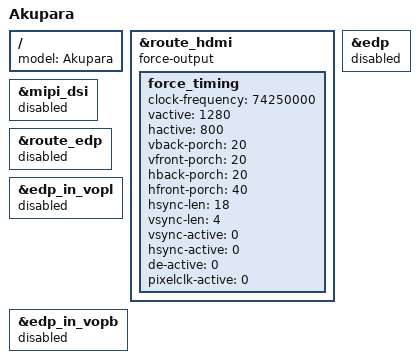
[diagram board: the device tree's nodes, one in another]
/*
 * (C) Copyright 2016 Rockchip Electronics Co., Ltd
 *
 * SPDX-License-Identifier:     GPL-2.0+
 */

/dts-v1/;
#include "rockpi-4b.dts"

/ {
	model = "Akupara";
};

&route_hdmi {
	status = "okay";
	force-output;

	force_timing {
		status = "okay";
		clock-frequency = <74250000>;
		vactive = <1280>;
		hactive = <800>;
		vback-porch = <20>;
		vfront-porch = <20>;
		hback-porch = <20>;
		hfront-porch = <40>;
		hsync-len = <18>;
		vsync-len = <4>;
		vsync-active = <0>;
		hsync-active = <0>;
		de-active = <0>;
		pixelclk-active = <0>;
	};
};

&mipi_dsi {
	status = "disabled";
};

&route_edp {
	status = "disabled";
};

&edp_in_vopl {
	status = "disabled";
};

&edp_in_vopb {
	status = "disabled";
};

&edp {
	status = "disabled";
};
